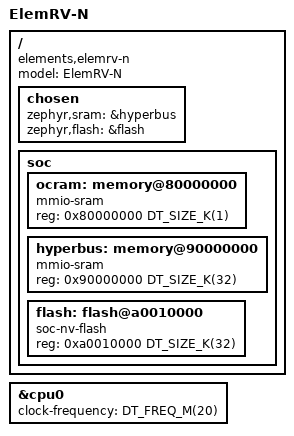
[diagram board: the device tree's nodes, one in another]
/*
 * Copyright (C) 2025 aesc silicon
 *
 * SPDX-License-Identifier: Apache-2.0
 */

/dts-v1/;

#include <elements/elemrv-n.dtsi>

/ {
	model = "ElemRV-N";
	compatible = "elements,elemrv-n";

	chosen {
		zephyr,sram = &hyperbus;
		zephyr,flash = &flash;
	};

	soc {
		ocram: memory@80000000 {
			device_type = "memory";
			compatible = "mmio-sram";
			reg = <0x80000000 DT_SIZE_K(1)>;
		};

		hyperbus: memory@90000000 {
			device_type = "memory";
			compatible = "mmio-sram";
			reg = <0x90000000 DT_SIZE_K(32)>;
		};

		flash: flash@a0010000 {
			compatible = "soc-nv-flash";
			reg = <0xa0010000 DT_SIZE_K(32)>;
		};
	};
};

&cpu0 {
	clock-frequency = <DT_FREQ_M(20)>;
};
